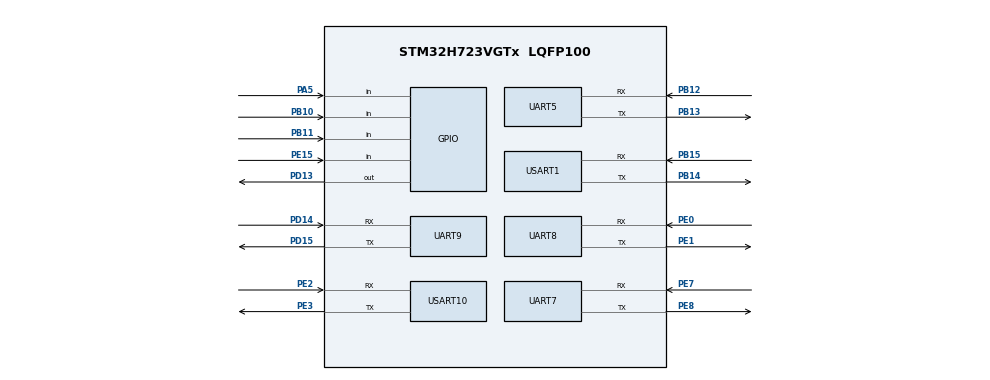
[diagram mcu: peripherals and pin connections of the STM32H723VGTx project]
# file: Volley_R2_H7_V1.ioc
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CORTEX_M7.default_mode_Activation=0
Dma.Request0=USART1_RX
Dma.Request1=USART1_TX
Dma.Request10=UART7_RX
Dma.Request11=UART7_TX
Dma.Request2=USART10_RX
Dma.Request3=USART10_TX
Dma.Request4=UART5_RX
Dma.Request5=UART5_TX
Dma.Request6=UART8_RX
Dma.Request7=UART8_TX
Dma.Request8=UART9_RX
Dma.Request9=UART9_TX
Dma.UART5_RX.4.Direction=DMA_PERIPH_TO_MEMORY
Dma.UART5_RX.4.EventEnable=DISABLE
Dma.UART5_RX.4.FIFOMode=DMA_FIFOMODE_DISABLE
Dma.UART5_RX.4.Instance=DMA1_Stream6
Dma.UART5_RX.4.MemDataAlignment=DMA_MDATAALIGN_BYTE
Dma.UART5_RX.4.MemInc=DMA_MINC_ENABLE
Dma.UART5_RX.4.Mode=DMA_NORMAL
Dma.UART5_RX.4.PeriphDataAlignment=DMA_PDATAALIGN_BYTE
Dma.UART5_RX.4.PeriphInc=DMA_PINC_DISABLE
Dma.UART5_RX.4.Polarity=HAL_DMAMUX_REQ_GEN_RISING
Dma.UART5_RX.4.Priority=DMA_PRIORITY_LOW
Dma.UART5_RX.4.RequestNumber=1
Dma.UART5_RX.4.SignalID=NONE
Dma.UART5_RX.4.SyncEnable=DISABLE
Dma.UART5_RX.4.SyncPolarity=HAL_DMAMUX_SYNC_NO_EVENT
Dma.UART5_RX.4.SyncRequestNumber=1
Dma.UART5_RX.4.SyncSignalID=NONE
Dma.UART5_TX.5.Direction=DMA_MEMORY_TO_PERIPH
Dma.UART5_TX.5.EventEnable=DISABLE
Dma.UART5_TX.5.FIFOMode=DMA_FIFOMODE_DISABLE
Dma.UART5_TX.5.Instance=DMA1_Stream7
Dma.UART5_TX.5.MemDataAlignment=DMA_MDATAALIGN_BYTE
Dma.UART5_TX.5.MemInc=DMA_MINC_ENABLE
Dma.UART5_TX.5.Mode=DMA_NORMAL
Dma.UART5_TX.5.PeriphDataAlignment=DMA_PDATAALIGN_BYTE
Dma.UART5_TX.5.PeriphInc=DMA_PINC_DISABLE
Dma.UART5_TX.5.Polarity=HAL_DMAMUX_REQ_GEN_RISING
Dma.UART5_TX.5.Priority=DMA_PRIORITY_LOW
Dma.UART5_TX.5.RequestNumber=1
Dma.UART5_TX.5.SignalID=NONE
Dma.UART5_TX.5.SyncEnable=DISABLE
Dma.UART5_TX.5.SyncPolarity=HAL_DMAMUX_SYNC_NO_EVENT
Dma.UART5_TX.5.SyncRequestNumber=1
Dma.UART5_TX.5.SyncSignalID=NONE
Dma.UART7_RX.10.Direction=DMA_PERIPH_TO_MEMORY
Dma.UART7_RX.10.EventEnable=DISABLE
Dma.UART7_RX.10.FIFOMode=DMA_FIFOMODE_DISABLE
Dma.UART7_RX.10.Instance=DMA1_Stream4
Dma.UART7_RX.10.MemDataAlignment=DMA_MDATAALIGN_BYTE
Dma.UART7_RX.10.MemInc=DMA_MINC_ENABLE
Dma.UART7_RX.10.Mode=DMA_NORMAL
Dma.UART7_RX.10.PeriphDataAlignment=DMA_PDATAALIGN_BYTE
Dma.UART7_RX.10.PeriphInc=DMA_PINC_DISABLE
Dma.UART7_RX.10.Polarity=HAL_DMAMUX_REQ_GEN_RISING
Dma.UART7_RX.10.Priority=DMA_PRIORITY_LOW
Dma.UART7_RX.10.RequestNumber=1
Dma.UART7_RX.10.SignalID=NONE
Dma.UART7_RX.10.SyncEnable=DISABLE
Dma.UART7_RX.10.SyncPolarity=HAL_DMAMUX_SYNC_NO_EVENT
Dma.UART7_RX.10.SyncRequestNumber=1
Dma.UART7_RX.10.SyncSignalID=NONE
Dma.UART7_TX.11.Direction=DMA_MEMORY_TO_PERIPH
Dma.UART7_TX.11.EventEnable=DISABLE
Dma.UART7_TX.11.FIFOMode=DMA_FIFOMODE_DISABLE
Dma.UART7_TX.11.Instance=DMA1_Stream5
Dma.UART7_TX.11.MemDataAlignment=DMA_MDATAALIGN_BYTE
Dma.UART7_TX.11.MemInc=DMA_MINC_ENABLE
Dma.UART7_TX.11.Mode=DMA_NORMAL
Dma.UART7_TX.11.PeriphDataAlignment=DMA_PDATAALIGN_BYTE
Dma.UART7_TX.11.PeriphInc=DMA_PINC_DISABLE
Dma.UART7_TX.11.Polarity=HAL_DMAMUX_REQ_GEN_RISING
Dma.UART7_TX.11.Priority=DMA_PRIORITY_LOW
Dma.UART7_TX.11.RequestNumber=1
Dma.UART7_TX.11.SignalID=NONE
Dma.UART7_TX.11.SyncEnable=DISABLE
Dma.UART7_TX.11.SyncPolarity=HAL_DMAMUX_SYNC_NO_EVENT
Dma.UART7_TX.11.SyncRequestNumber=1
Dma.UART7_TX.11.SyncSignalID=NONE
Dma.UART8_RX.6.Direction=DMA_PERIPH_TO_MEMORY
Dma.UART8_RX.6.EventEnable=DISABLE
Dma.UART8_RX.6.FIFOMode=DMA_FIFOMODE_DISABLE
Dma.UART8_RX.6.Instance=DMA2_Stream0
Dma.UART8_RX.6.MemDataAlignment=DMA_MDATAALIGN_BYTE
Dma.UART8_RX.6.MemInc=DMA_MINC_ENABLE
Dma.UART8_RX.6.Mode=DMA_NORMAL
Dma.UART8_RX.6.PeriphDataAlignment=DMA_PDATAALIGN_BYTE
Dma.UART8_RX.6.PeriphInc=DMA_PINC_DISABLE
Dma.UART8_RX.6.Polarity=HAL_DMAMUX_REQ_GEN_RISING
Dma.UART8_RX.6.Priority=DMA_PRIORITY_LOW
Dma.UART8_RX.6.RequestNumber=1
Dma.UART8_RX.6.SignalID=NONE
Dma.UART8_RX.6.SyncEnable=DISABLE
Dma.UART8_RX.6.SyncPolarity=HAL_DMAMUX_SYNC_NO_EVENT
Dma.UART8_RX.6.SyncRequestNumber=1
Dma.UART8_RX.6.SyncSignalID=NONE
Dma.UART8_TX.7.Direction=DMA_MEMORY_TO_PERIPH
Dma.UART8_TX.7.EventEnable=DISABLE
Dma.UART8_TX.7.FIFOMode=DMA_FIFOMODE_DISABLE
Dma.UART8_TX.7.Instance=DMA2_Stream1
Dma.UART8_TX.7.MemDataAlignment=DMA_MDATAALIGN_BYTE
Dma.UART8_TX.7.MemInc=DMA_MINC_ENABLE
Dma.UART8_TX.7.Mode=DMA_NORMAL
Dma.UART8_TX.7.PeriphDataAlignment=DMA_PDATAALIGN_BYTE
Dma.UART8_TX.7.PeriphInc=DMA_PINC_DISABLE
Dma.UART8_TX.7.Polarity=HAL_DMAMUX_REQ_GEN_RISING
Dma.UART8_TX.7.Priority=DMA_PRIORITY_LOW
Dma.UART8_TX.7.RequestNumber=1
Dma.UART8_TX.7.SignalID=NONE
Dma.UART8_TX.7.SyncEnable=DISABLE
Dma.UART8_TX.7.SyncPolarity=HAL_DMAMUX_SYNC_NO_EVENT
Dma.UART8_TX.7.SyncRequestNumber=1
Dma.UART8_TX.7.SyncSignalID=NONE
Dma.UART9_RX.8.Direction=DMA_PERIPH_TO_MEMORY
Dma.UART9_RX.8.EventEnable=DISABLE
Dma.UART9_RX.8.FIFOMode=DMA_FIFOMODE_DISABLE
Dma.UART9_RX.8.Instance=DMA2_Stream2
Dma.UART9_RX.8.MemDataAlignment=DMA_MDATAALIGN_BYTE
Dma.UART9_RX.8.MemInc=DMA_MINC_ENABLE
Dma.UART9_RX.8.Mode=DMA_NORMAL
Dma.UART9_RX.8.PeriphDataAlignment=DMA_PDATAALIGN_BYTE
Dma.UART9_RX.8.PeriphInc=DMA_PINC_DISABLE
Dma.UART9_RX.8.Polarity=HAL_DMAMUX_REQ_GEN_RISING
Dma.UART9_RX.8.Priority=DMA_PRIORITY_LOW
Dma.UART9_RX.8.RequestNumber=1
Dma.UART9_RX.8.SignalID=NONE
Dma.UART9_RX.8.SyncEnable=DISABLE
Dma.UART9_RX.8.SyncPolarity=HAL_DMAMUX_SYNC_NO_EVENT
Dma.UART9_RX.8.SyncRequestNumber=1
Dma.UART9_RX.8.SyncSignalID=NONE
Dma.UART9_TX.9.Direction=DMA_MEMORY_TO_PERIPH
Dma.UART9_TX.9.EventEnable=DISABLE
Dma.UART9_TX.9.FIFOMode=DMA_FIFOMODE_DISABLE
Dma.UART9_TX.9.Instance=DMA2_Stream3
Dma.UART9_TX.9.MemDataAlignment=DMA_MDATAALIGN_BYTE
Dma.UART9_TX.9.MemInc=DMA_MINC_ENABLE
Dma.UART9_TX.9.Mode=DMA_NORMAL
Dma.UART9_TX.9.PeriphDataAlignment=DMA_PDATAALIGN_BYTE
Dma.UART9_TX.9.PeriphInc=DMA_PINC_DISABLE
Dma.UART9_TX.9.Polarity=HAL_DMAMUX_REQ_GEN_RISING
Dma.UART9_TX.9.Priority=DMA_PRIORITY_LOW
Dma.UART9_TX.9.RequestNumber=1
Dma.UART9_TX.9.SignalID=NONE
Dma.UART9_TX.9.SyncEnable=DISABLE
Dma.UART9_TX.9.SyncPolarity=HAL_DMAMUX_SYNC_NO_EVENT
Dma.UART9_TX.9.SyncRequestNumber=1
Dma.UART9_TX.9.SyncSignalID=NONE
Dma.USART10_RX.2.Direction=DMA_PERIPH_TO_MEMORY
Dma.USART10_RX.2.EventEnable=DISABLE
Dma.USART10_RX.2.FIFOMode=DMA_FIFOMODE_DISABLE
Dma.USART10_RX.2.Instance=DMA1_Stream2
Dma.USART10_RX.2.MemDataAlignment=DMA_MDATAALIGN_BYTE
Dma.USART10_RX.2.MemInc=DMA_MINC_ENABLE
Dma.USART10_RX.2.Mode=DMA_NORMAL
Dma.USART10_RX.2.PeriphDataAlignment=DMA_PDATAALIGN_BYTE
Dma.USART10_RX.2.PeriphInc=DMA_PINC_DISABLE
Dma.USART10_RX.2.Polarity=HAL_DMAMUX_REQ_GEN_RISING
Dma.USART10_RX.2.Priority=DMA_PRIORITY_LOW
Dma.USART10_RX.2.RequestNumber=1
Dma.USART10_RX.2.SignalID=NONE
Dma.USART10_RX.2.SyncEnable=DISABLE
Dma.USART10_RX.2.SyncPolarity=HAL_DMAMUX_SYNC_NO_EVENT
Dma.USART10_RX.2.SyncRequestNumber=1
Dma.USART10_RX.2.SyncSignalID=NONE
Dma.USART10_TX.3.Direction=DMA_MEMORY_TO_PERIPH
Dma.USART10_TX.3.EventEnable=DISABLE
Dma.USART10_TX.3.FIFOMode=DMA_FIFOMODE_DISABLE
Dma.USART10_TX.3.Instance=DMA1_Stream3
Dma.USART10_TX.3.MemDataAlignment=DMA_MDATAALIGN_BYTE
Dma.USART10_TX.3.MemInc=DMA_MINC_ENABLE
Dma.USART10_TX.3.Mode=DMA_NORMAL
Dma.USART10_TX.3.PeriphDataAlignment=DMA_PDATAALIGN_BYTE
Dma.USART10_TX.3.PeriphInc=DMA_PINC_DISABLE
Dma.USART10_TX.3.Polarity=HAL_DMAMUX_REQ_GEN_RISING
Dma.USART10_TX.3.Priority=DMA_PRIORITY_LOW
Dma.USART10_TX.3.RequestNumber=1
Dma.USART10_TX.3.SignalID=NONE
Dma.USART10_TX.3.SyncEnable=DISABLE
Dma.USART10_TX.3.SyncPolarity=HAL_DMAMUX_SYNC_NO_EVENT
Dma.USART10_TX.3.SyncRequestNumber=1
Dma.USART10_TX.3.SyncSignalID=NONE
Dma.USART1_RX.0.Direction=DMA_PERIPH_TO_MEMORY
Dma.USART1_RX.0.EventEnable=DISABLE
Dma.USART1_RX.0.FIFOMode=DMA_FIFOMODE_DISABLE
Dma.USART1_RX.0.Instance=DMA1_Stream0
Dma.USART1_RX.0.MemDataAlignment=DMA_MDATAALIGN_BYTE
Dma.USART1_RX.0.MemInc=DMA_MINC_ENABLE
Dma.USART1_RX.0.Mode=DMA_NORMAL
Dma.USART1_RX.0.PeriphDataAlignment=DMA_PDATAALIGN_BYTE
Dma.USART1_RX.0.PeriphInc=DMA_PINC_DISABLE
Dma.USART1_RX.0.Polarity=HAL_DMAMUX_REQ_GEN_RISING
Dma.USART1_RX.0.Priority=DMA_PRIORITY_LOW
Dma.USART1_RX.0.RequestNumber=1
Dma.USART1_RX.0.SignalID=NONE
Dma.USART1_RX.0.SyncEnable=DISABLE
Dma.USART1_RX.0.SyncPolarity=HAL_DMAMUX_SYNC_NO_EVENT
Dma.USART1_RX.0.SyncRequestNumber=1
Dma.USART1_RX.0.SyncSignalID=NONE
Dma.USART1_TX.1.Direction=DMA_MEMORY_TO_PERIPH
Dma.USART1_TX.1.EventEnable=DISABLE
Dma.USART1_TX.1.FIFOMode=DMA_FIFOMODE_DISABLE
Dma.USART1_TX.1.Instance=DMA1_Stream1
Dma.USART1_TX.1.MemDataAlignment=DMA_MDATAALIGN_BYTE
Dma.USART1_TX.1.MemInc=DMA_MINC_ENABLE
Dma.USART1_TX.1.Mode=DMA_NORMAL
Dma.USART1_TX.1.PeriphDataAlignment=DMA_PDATAALIGN_BYTE
Dma.USART1_TX.1.PeriphInc=DMA_PINC_DISABLE
Dma.USART1_TX.1.Polarity=HAL_DMAMUX_REQ_GEN_RISING
Dma.USART1_TX.1.Priority=DMA_PRIORITY_LOW
Dma.USART1_TX.1.RequestNumber=1
Dma.USART1_TX.1.SignalID=NONE
Dma.USART1_TX.1.SyncEnable=DISABLE
Dma.USART1_TX.1.SyncPolarity=HAL_DMAMUX_SYNC_NO_EVENT
Dma.USART1_TX.1.SyncRequestNumber=1
Dma.USART1_TX.1.SyncSignalID=NONE
FREERTOS.Tasks01=defaultTask,24,128,StartDefaultTask,Default,NULL,Dynamic,NULL,NULL
Mcu.Family=STM32H7
Mcu.Name=STM32H723VGTx
Mcu.Package=LQFP100
NVIC.DMA1_Stream0_IRQn=true\:5\:0\:false\:false\:true\:true\:false\:true\:true
NVIC.DMA1_Stream1_IRQn=true\:5\:0\:false\:false\:true\:true\:false\:true\:true
NVIC.DMA1_Stream2_IRQn=true\:5\:0\:false\:false\:true\:true\:false\:true\:true
NVIC.DMA1_Stream3_IRQn=true\:5\:0\:false\:false\:true\:true\:false\:true\:true
NVIC.DMA1_Stream4_IRQn=true\:5\:0\:false\:false\:true\:true\:false\:true\:true
NVIC.DMA1_Stream5_IRQn=true\:5\:0\:false\:false\:true\:true\:false\:true\:true
NVIC.DMA1_Stream6_IRQn=true\:5\:0\:false\:false\:true\:true\:false\:true\:true
NVIC.DMA1_Stream7_IRQn=true\:5\:0\:false\:false\:true\:true\:false\:true\:true
NVIC.DMA2_Stream0_IRQn=true\:5\:0\:false\:false\:true\:true\:false\:true\:true
NVIC.DMA2_Stream1_IRQn=true\:5\:0\:false\:false\:true\:true\:false\:true\:true
NVIC.DMA2_Stream2_IRQn=true\:5\:0\:false\:false\:true\:true\:false\:true\:true
NVIC.DMA2_Stream3_IRQn=true\:5\:0\:false\:false\:true\:true\:false\:true\:true
NVIC.PriorityGroup=NVIC_PRIORITYGROUP_4
NVIC.TIM1_UP_IRQn=true\:15\:0\:false\:false\:true\:false\:false\:true\:true
NVIC.TimeBase=TIM1_UP_IRQn
NVIC.TimeBaseIP=TIM1
NVIC.UART5_IRQn=true\:5\:0\:false\:false\:true\:true\:true\:true\:true
NVIC.UART7_IRQn=true\:5\:0\:false\:false\:true\:true\:true\:true\:true
NVIC.UART8_IRQn=true\:5\:0\:false\:false\:true\:true\:true\:true\:true
NVIC.UART9_IRQn=true\:5\:0\:false\:false\:true\:true\:true\:true\:true
NVIC.USART10_IRQn=true\:5\:0\:false\:false\:true\:true\:true\:true\:true
NVIC.USART1_IRQn=true\:5\:0\:false\:false\:true\:true\:true\:true\:true
PA5.Signal=GPIO_Input
PB10.Signal=GPIO_Input
PB11.Signal=GPIO_Input
PB12.Mode=Asynchronous
PB12.Signal=UART5_RX
PB13.Mode=Asynchronous
PB13.Signal=UART5_TX
PB14.Mode=Asynchronous
PB14.Signal=USART1_TX
PB15.Mode=Asynchronous
PB15.Signal=USART1_RX
PD13.Signal=GPIO_Output
PD14.Mode=Asynchronous
PD14.Signal=UART9_RX
PD15.Mode=Asynchronous
PD15.Signal=UART9_TX
PE0.Mode=Asynchronous
PE0.Signal=UART8_RX
PE1.Mode=Asynchronous
PE1.Signal=UART8_TX
PE15.Signal=GPIO_Input
PE2.Mode=Asynchronous
PE2.Signal=USART10_RX
PE3.Mode=Asynchronous
PE3.Signal=USART10_TX
PE7.Mode=Asynchronous
PE7.Signal=UART7_RX
PE8.Mode=Asynchronous
PE8.Signal=UART7_TX
PH0-OSC_IN.Mode=HSE-External-Oscillator
PH0-OSC_IN.Signal=RCC_OSC_IN
PH1-OSC_OUT.Mode=HSE-External-Oscillator
PH1-OSC_OUT.Signal=RCC_OSC_OUT
ProjectManager.HeapSize=0x200
ProjectManager.StackSize=0x400
ProjectManager.TargetToolchain=MDK-ARM V5.32
RCC.ADCFreq_Value=129000000
RCC.APB1Freq_Value=137500000
RCC.APB2Freq_Value=137500000
RCC.APB3Freq_Value=137500000
RCC.APB4Freq_Value=137500000
RCC.CortexFreq_Value=550000000
RCC.D1PPRE=RCC_APB3_DIV2
RCC.D2PPRE1=RCC_APB1_DIV2
RCC.D2PPRE2=RCC_APB2_DIV2
RCC.D3PPRE=RCC_APB4_DIV2
RCC.DIVM1=4
RCC.DIVN1=34
RCC.DIVP1=1
RCC.DIVQ1=4
RCC.FDCANCLockSelection=RCC_FDCANCLKSOURCE_PLL2
RCC.HCLKFreq_Value=275000000
RCC.HPRE=RCC_HCLK_DIV2
RCC.PLL1_VCO_SEL-AdvancedSettings=RCC_PLL1VCOWIDE
RCC.PLL2FRACN=0
RCC.PLL3FRACN=0
RCC.PLLFRACN=3072
RCC.SYSCLKFreq_VALUE=550000000
RCC.SYSCLKSource=RCC_SYSCLKSOURCE_PLLCLK
RCC.USBFreq_Value=137500000
USART1.VirtualMode-Asynchronous=VM_ASYNC
USART10.VirtualMode=VM_ASYNC
VP_FREERTOS_VS_CMSIS_V2.Mode=CMSIS_V2
VP_MEMORYMAP_VS_MEMORYMAP.Mode=CurAppReg
VP_SYS_VS_tim1.Mode=TIM1
board=custom

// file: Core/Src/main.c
/* USER CODE BEGIN Header */
/**
  ******************************************************************************
  * @file           : main.c
  * @brief          : Main program body
  ******************************************************************************
  * @attention
  *
  * Copyright (c) 2026 STMicroelectronics.
  * All rights reserved.
  *
  * This software is licensed under terms that can be found in the LICENSE file
  * in the root directory of this software component.
  * If no LICENSE file comes with this software, it is provided AS-IS.
  *
  ******************************************************************************
  */
/* USER CODE END Header */
#include "main.h"
#include "FreeRTOS.h"
#include "cmsis_os2.h"
#include "dma.h"
#include "usart.h"
#include "gpio.h"

void SystemClock_Config(void);
void MX_FREERTOS_Init(void);

int main(void)
{

  /* MCU Configuration--------------------------------------------------------*/

  /* Reset of all peripherals, Initializes the Flash interface and the Systick. */
  HAL_Init();

  /* Configure the system clock */
  SystemClock_Config();

  /* Initialize all configured peripherals */
  MX_GPIO_Init();
  MX_DMA_Init();
  MX_UART7_Init();
  MX_USART1_UART_Init();
  MX_USART10_UART_Init();
  MX_UART5_Init();
  MX_UART8_Init();
  MX_UART9_Init();

  /* Init scheduler */
  osKernelInitialize();  /* Call init function for freertos objects (in cmsis_os2.c) */
  MX_FREERTOS_Init();

  /* Start scheduler */
  osKernelStart();

  /* We should never get here as control is now taken by the scheduler */

  /* Infinite loop */
  while (1)
  {

  }
}

void SystemClock_Config(void)
{
  RCC_OscInitTypeDef RCC_OscInitStruct = {0};
  RCC_ClkInitTypeDef RCC_ClkInitStruct = {0};

  /** Supply configuration update enable
  */
  HAL_PWREx_ConfigSupply(PWR_LDO_SUPPLY);

  /** Configure the main internal regulator output voltage
  */
  __HAL_PWR_VOLTAGESCALING_CONFIG(PWR_REGULATOR_VOLTAGE_SCALE0);

  while(!__HAL_PWR_GET_FLAG(PWR_FLAG_VOSRDY)) {}

  /** Initializes the RCC Oscillators according to the specified parameters
  * in the RCC_OscInitTypeDef structure.
  */
  RCC_OscInitStruct.OscillatorType = RCC_OSCILLATORTYPE_HSI;
  RCC_OscInitStruct.HSIState = RCC_HSI_DIV1;
  RCC_OscInitStruct.HSICalibrationValue = 64;
  RCC_OscInitStruct.PLL.PLLState = RCC_PLL_ON;
  RCC_OscInitStruct.PLL.PLLSource = RCC_PLLSOURCE_HSI;
  RCC_OscInitStruct.PLL.PLLM = 4;
  RCC_OscInitStruct.PLL.PLLN = 34;
  RCC_OscInitStruct.PLL.PLLP = 1;
  RCC_OscInitStruct.PLL.PLLQ = 4;
  RCC_OscInitStruct.PLL.PLLR = 2;
  RCC_OscInitStruct.PLL.PLLRGE = RCC_PLL1VCIRANGE_3;
  RCC_OscInitStruct.PLL.PLLVCOSEL = RCC_PLL1VCOWIDE;
  RCC_OscInitStruct.PLL.PLLFRACN = 3072;
  if (HAL_RCC_OscConfig(&RCC_OscInitStruct) != HAL_OK)
  {
    Error_Handler();
  }

  /** Initializes the CPU, AHB and APB buses clocks
  */
  RCC_ClkInitStruct.ClockType = RCC_CLOCKTYPE_HCLK|RCC_CLOCKTYPE_SYSCLK
                              |RCC_CLOCKTYPE_PCLK1|RCC_CLOCKTYPE_PCLK2
                              |RCC_CLOCKTYPE_D3PCLK1|RCC_CLOCKTYPE_D1PCLK1;
  RCC_ClkInitStruct.SYSCLKSource = RCC_SYSCLKSOURCE_PLLCLK;
  RCC_ClkInitStruct.SYSCLKDivider = RCC_SYSCLK_DIV1;
  RCC_ClkInitStruct.AHBCLKDivider = RCC_HCLK_DIV2;
  RCC_ClkInitStruct.APB3CLKDivider = RCC_APB3_DIV2;
  RCC_ClkInitStruct.APB1CLKDivider = RCC_APB1_DIV2;
  RCC_ClkInitStruct.APB2CLKDivider = RCC_APB2_DIV2;
  RCC_ClkInitStruct.APB4CLKDivider = RCC_APB4_DIV2;

  if (HAL_RCC_ClockConfig(&RCC_ClkInitStruct, FLASH_LATENCY_3) != HAL_OK)
  {
    Error_Handler();
  }
}

void HAL_TIM_PeriodElapsedCallback(TIM_HandleTypeDef *htim)
{
  if (htim->Instance == TIM1)
  {
    HAL_IncTick();
  }
}

void Error_Handler(void)
{
  __disable_irq();
  while (1)
  {
  }
}

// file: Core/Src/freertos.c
/* USER CODE BEGIN Header */
/**
  ******************************************************************************
  * File Name          : freertos.c
  * Description        : Code for freertos applications
  ******************************************************************************
  * @attention
  *
  * Copyright (c) 2026 STMicroelectronics.
  * All rights reserved.
  *
  * This software is licensed under terms that can be found in the LICENSE file
  * in the root directory of this software component.
  * If no LICENSE file comes with this software, it is provided AS-IS.
  *
  ******************************************************************************
  */
/* USER CODE END Header */

#include "FreeRTOS.h"
#include "task.h"
#include "main.h"
#include "FreeRTOS.h"
#include "cmsis_os2.h"

/* USER CODE BEGIN Includes */
#include "semphr.h"
#include "Task_Init.h"
/* USER CODE END Includes */

/* USER CODE BEGIN PD */
SemaphoreHandle_t remote_semaphore;
SemaphoreHandle_t action_semaphore;
SemaphoreHandle_t g_EncoderMutex;
/* USER CODE END PD */

/* USER CODE BEGIN Variables */
TaskHandle_t ZDT_Parse_RunHandle;
/* USER CODE END Variables */
/* Definitions for defaultTask */
osThreadId_t defaultTaskHandle;
const osThreadAttr_t defaultTask_attributes = {
  .name = "defaultTask",
  .stack_size = 128 * 4,
  .priority = (osPriority_t) osPriorityNormal,
};

void StartDefaultTask(void *argument);

void MX_FREERTOS_Init(void); /* (MISRA C 2004 rule 8.1) */

void MX_FREERTOS_Init(void) {

  /* USER CODE BEGIN RTOS_SEMAPHORES */
  /* add semaphores, ... */
remote_semaphore=xSemaphoreCreateBinary();
action_semaphore=xSemaphoreCreateBinary();

  /* USER CODE END RTOS_SEMAPHORES */

  /* Create the thread(s) */
  /* creation of defaultTask */
  defaultTaskHandle = osThreadNew(StartDefaultTask, NULL, &defaultTask_attributes);

}

void StartDefaultTask(void *argument)
{
  /* USER CODE BEGIN StartDefaultTask */
	Task_Init();
	vTaskDelete(NULL);
  /* Infinite loop */
  for(;;)
  {
    osDelay(1);
  }
  /* USER CODE END StartDefaultTask */
}
